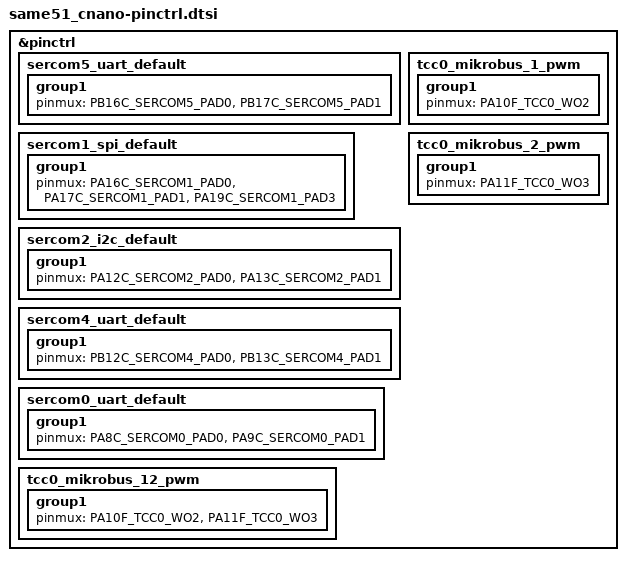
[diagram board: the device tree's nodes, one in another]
/*
 * SAM E51 Curiosity Nano (EV76S68A) pin muxing.
 * Source: SAM E51 Curiosity Nano User Guide DS70005432B, fig. 4-1 / 4-2.
 * SPDX-License-Identifier: Apache-2.0
 */

#include <dt-bindings/pinctrl/same51j-pinctrl.h>

&pinctrl {
	/* nEDBG virtual COM port: PB16 = SERCOM5 PAD0 (TX), PB17 = SERCOM5 PAD1 (RX) */
	sercom5_uart_default: sercom5_uart_default {
		group1 {
			pinmux = <PB16C_SERCOM5_PAD0>,
				 <PB17C_SERCOM5_PAD1>;
		};
	};

	/* mikroBUS SPI, shared by all three slots:
	 * PA16 = PAD0 MOSI, PA17 = PAD1 SCK, PA19 = PAD3 MISO. CS lines are GPIOs.
	 */
	sercom1_spi_default: sercom1_spi_default {
		group1 {
			pinmux = <PA16C_SERCOM1_PAD0>,
				 <PA17C_SERCOM1_PAD1>,
				 <PA19C_SERCOM1_PAD3>;
		};
	};

	/* mikroBUS I2C, shared by all three slots: PA12 = PAD0 SDA, PA13 = PAD1 SCL */
	sercom2_i2c_default: sercom2_i2c_default {
		group1 {
			pinmux = <PA12C_SERCOM2_PAD0>,
				 <PA13C_SERCOM2_PAD1>;
		};
	};

	/* mikroBUS UART of slots 1 and 3 (shared): PB12 = PAD0 TX, PB13 = PAD1 RX */
	sercom4_uart_default: sercom4_uart_default {
		group1 {
			pinmux = <PB12C_SERCOM4_PAD0>,
				 <PB13C_SERCOM4_PAD1>;
		};
	};

	/* mikroBUS UART of slot 2: PA8 = PAD0 TX, PA9 = PAD1 RX */
	sercom0_uart_default: sercom0_uart_default {
		group1 {
			pinmux = <PA8C_SERCOM0_PAD0>,
				 <PA9C_SERCOM0_PAD1>;
		};
	};

	/* mikroBUS PWM: slot 1 PA10 = TCC0 WO2 (ch 2), slot 2 PA11 = TCC0 WO3 (ch 3).
	 * Slot 3 PWM (PB9) only reaches TC4 WO1, which has no Zephyr PWM driver.
	 */
	tcc0_mikrobus_1_pwm: tcc0_mikrobus_1_pwm {
		group1 {
			pinmux = <PA10F_TCC0_WO2>;
		};
	};

	tcc0_mikrobus_2_pwm: tcc0_mikrobus_2_pwm {
		group1 {
			pinmux = <PA11F_TCC0_WO3>;
		};
	};

	tcc0_mikrobus_12_pwm: tcc0_mikrobus_12_pwm {
		group1 {
			pinmux = <PA10F_TCC0_WO2>,
				 <PA11F_TCC0_WO3>;
		};
	};
};
